# NPCX490M register map
File version: 1.0
Registers are 8-bit, read-write, reset 0x0 unless marked. A register's access mark holds for its fields unless they carry their own. Offsets are from the block's base; [hi:lo] are bit positions; {n}, {i} and the like mark numbered series.

## MDC
Base 0x4000C000
0x0A HEAD_BASEL 16-bit (reset mask 0xFF) — Header Base Low Register (HEAD_BASEL)
0x0C HEAD_BASEH 16-bit (reset mask 0xFF) — Header Base High Register (HEAD_BASEH)
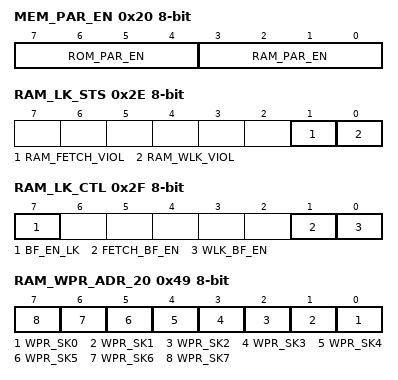
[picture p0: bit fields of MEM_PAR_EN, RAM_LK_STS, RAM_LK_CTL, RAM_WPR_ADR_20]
0x20 MEM_PAR_EN — Memory Parity Check Enable Register (MEM_PAR_EN)
  [7:4] ROM_PAR_EN — ROM Parity Check Enable
  [3:0] RAM_PAR_EN — RAM Parity Check Enable
0x22 FWSC — Firmware Scratch Register (FWSC)
0x2E RAM_LK_STS — RAM Lock Status Register (RAM_LK_STS)
  [1] RAM_FETCH_VIOL — RAM Fetch Violation
  [0] RAM_WLK_VIOL — RAM Write Lock Violation
0x2F RAM_LK_CTL — RAM Lock Control Register (RAM_LK_CTL)
  [7] BF_EN_LK — BusFault Trap Enable Lock
  [1] FETCH_BF_EN — RAM Fetch BusFault Trap Enable
  [0] WLK_BF_EN — RAM Write Lock BusFault Trap Enable
0x49 RAM_WPR_ADR_20 — RAM Write Protect Block Base Address nn Register (RAM_WPR_ADR_nn)
  [n] WPR_SK{n} (n=0..7) — Write Protect Sector {n}
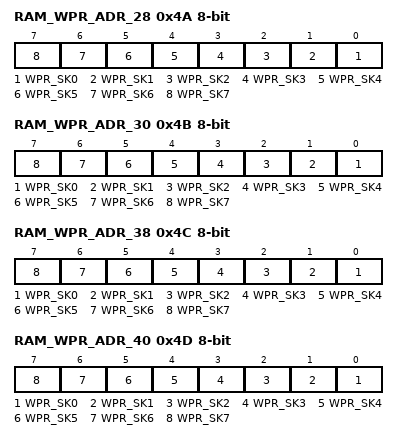
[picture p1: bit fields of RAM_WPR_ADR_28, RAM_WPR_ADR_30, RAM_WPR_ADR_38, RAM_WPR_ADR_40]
0x4A RAM_WPR_ADR_28 — RAM Write Protect Block Base Address nn Register (RAM_WPR_ADR_nn)
  [n] WPR_SK{n} (n=0..7) — Write Protect Sector {n}
0x4B RAM_WPR_ADR_30 — RAM Write Protect Block Base Address nn Register (RAM_WPR_ADR_nn)
  [n] WPR_SK{n} (n=0..7) — Write Protect Sector {n}
0x4C RAM_WPR_ADR_38 — RAM Write Protect Block Base Address nn Register (RAM_WPR_ADR_nn)
  [n] WPR_SK{n} (n=0..7) — Write Protect Sector {n}
0x4D RAM_WPR_ADR_40 — RAM Write Protect Block Base Address nn Register (RAM_WPR_ADR_nn)
  [n] WPR_SK{n} (n=0..7) — Write Protect Sector {n}
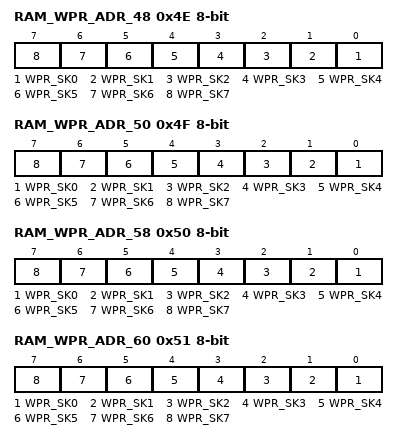
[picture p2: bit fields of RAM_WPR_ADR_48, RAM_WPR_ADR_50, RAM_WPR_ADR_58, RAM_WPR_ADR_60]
0x4E RAM_WPR_ADR_48 — RAM Write Protect Block Base Address nn Register (RAM_WPR_ADR_nn)
  [n] WPR_SK{n} (n=0..7) — Write Protect Sector {n}
0x4F RAM_WPR_ADR_50 — RAM Write Protect Block Base Address nn Register (RAM_WPR_ADR_nn)
  [n] WPR_SK{n} (n=0..7) — Write Protect Sector {n}
0x50 RAM_WPR_ADR_58 — RAM Write Protect Block Base Address nn Register (RAM_WPR_ADR_nn)
  [n] WPR_SK{n} (n=0..7) — Write Protect Sector {n}
0x51 RAM_WPR_ADR_60 — RAM Write Protect Block Base Address nn Register (RAM_WPR_ADR_nn)
  [n] WPR_SK{n} (n=0..7) — Write Protect Sector {n}
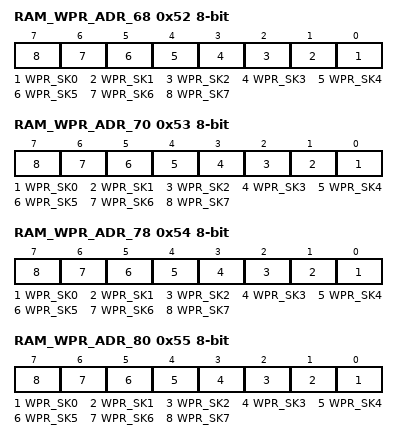
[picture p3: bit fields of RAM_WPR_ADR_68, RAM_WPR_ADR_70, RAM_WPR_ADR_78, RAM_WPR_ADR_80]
0x52 RAM_WPR_ADR_68 — RAM Write Protect Block Base Address nn Register (RAM_WPR_ADR_nn)
  [n] WPR_SK{n} (n=0..7) — Write Protect Sector {n}
0x53 RAM_WPR_ADR_70 — RAM Write Protect Block Base Address nn Register (RAM_WPR_ADR_nn)
  [n] WPR_SK{n} (n=0..7) — Write Protect Sector {n}
0x54 RAM_WPR_ADR_78 — RAM Write Protect Block Base Address nn Register (RAM_WPR_ADR_nn)
  [n] WPR_SK{n} (n=0..7) — Write Protect Sector {n}
0x55 RAM_WPR_ADR_80 — RAM Write Protect Block Base Address nn Register (RAM_WPR_ADR_nn)
  [n] WPR_SK{n} (n=0..7) — Write Protect Sector {n}
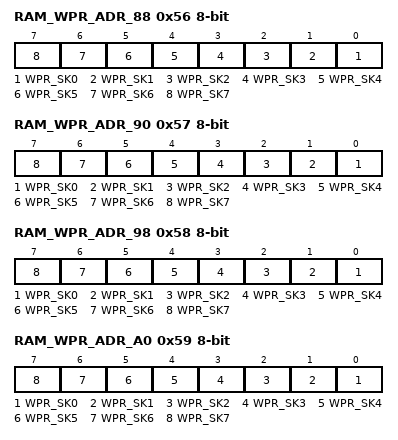
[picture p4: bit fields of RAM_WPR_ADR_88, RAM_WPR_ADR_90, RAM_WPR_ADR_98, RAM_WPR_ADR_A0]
0x56 RAM_WPR_ADR_88 — RAM Write Protect Block Base Address nn Register (RAM_WPR_ADR_nn)
  [n] WPR_SK{n} (n=0..7) — Write Protect Sector {n}
0x57 RAM_WPR_ADR_90 — RAM Write Protect Block Base Address nn Register (RAM_WPR_ADR_nn)
  [n] WPR_SK{n} (n=0..7) — Write Protect Sector {n}
0x58 RAM_WPR_ADR_98 — RAM Write Protect Block Base Address nn Register (RAM_WPR_ADR_nn)
  [n] WPR_SK{n} (n=0..7) — Write Protect Sector {n}
0x59 RAM_WPR_ADR_A0 — RAM Write Protect Block Base Address nn Register (RAM_WPR_ADR_nn)
  [n] WPR_SK{n} (n=0..7) — Write Protect Sector {n}
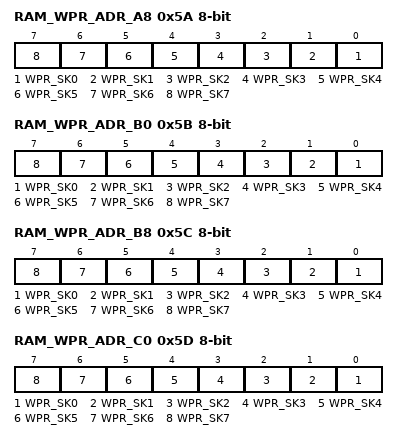
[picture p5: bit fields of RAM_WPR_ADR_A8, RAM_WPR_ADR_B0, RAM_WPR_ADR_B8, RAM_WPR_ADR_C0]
0x5A RAM_WPR_ADR_A8 — RAM Write Protect Block Base Address nn Register (RAM_WPR_ADR_nn)
  [n] WPR_SK{n} (n=0..7) — Write Protect Sector {n}
0x5B RAM_WPR_ADR_B0 — RAM Write Protect Block Base Address nn Register (RAM_WPR_ADR_nn)
  [n] WPR_SK{n} (n=0..7) — Write Protect Sector {n}
0x5C RAM_WPR_ADR_B8 — RAM Write Protect Block Base Address nn Register (RAM_WPR_ADR_nn)
  [n] WPR_SK{n} (n=0..7) — Write Protect Sector {n}
0x5D RAM_WPR_ADR_C0 — RAM Write Protect Block Base Address nn Register (RAM_WPR_ADR_nn)
  [n] WPR_SK{n} (n=0..7) — Write Protect Sector {n}
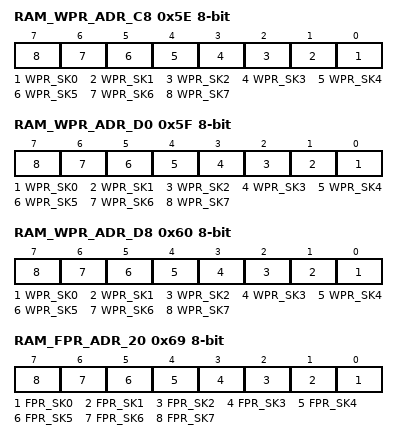
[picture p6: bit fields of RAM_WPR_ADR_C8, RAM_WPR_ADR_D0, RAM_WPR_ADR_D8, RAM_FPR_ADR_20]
0x5E RAM_WPR_ADR_C8 — RAM Write Protect Block Base Address nn Register (RAM_WPR_ADR_nn)
  [n] WPR_SK{n} (n=0..7) — Write Protect Sector {n}
0x5F RAM_WPR_ADR_D0 — RAM Write Protect Block Base Address nn Register (RAM_WPR_ADR_nn)
  [n] WPR_SK{n} (n=0..7) — Write Protect Sector {n}
0x60 RAM_WPR_ADR_D8 — RAM Write Protect Block Base Address nn Register (RAM_WPR_ADR_nn)
  [n] WPR_SK{n} (n=0..7) — Write Protect Sector {n}
0x69 RAM_FPR_ADR_20 — RAM Fetch Protect Block Base Address nn Register (RAM_FPR_ADR_nn)
  [n] FPR_SK{n} (n=0..7) — Fetch Protect Sector {n}
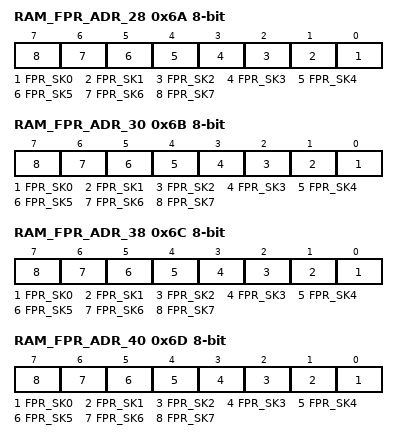
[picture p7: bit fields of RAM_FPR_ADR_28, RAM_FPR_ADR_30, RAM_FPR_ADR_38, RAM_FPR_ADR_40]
0x6A RAM_FPR_ADR_28 — RAM Fetch Protect Block Base Address nn Register (RAM_FPR_ADR_nn)
  [n] FPR_SK{n} (n=0..7) — Fetch Protect Sector {n}
0x6B RAM_FPR_ADR_30 — RAM Fetch Protect Block Base Address nn Register (RAM_FPR_ADR_nn)
  [n] FPR_SK{n} (n=0..7) — Fetch Protect Sector {n}
0x6C RAM_FPR_ADR_38 — RAM Fetch Protect Block Base Address nn Register (RAM_FPR_ADR_nn)
  [n] FPR_SK{n} (n=0..7) — Fetch Protect Sector {n}
0x6D RAM_FPR_ADR_40 — RAM Fetch Protect Block Base Address nn Register (RAM_FPR_ADR_nn)
  [n] FPR_SK{n} (n=0..7) — Fetch Protect Sector {n}
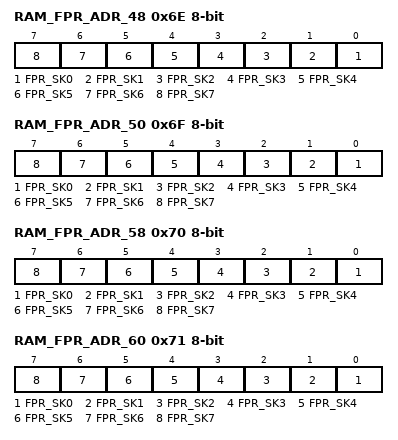
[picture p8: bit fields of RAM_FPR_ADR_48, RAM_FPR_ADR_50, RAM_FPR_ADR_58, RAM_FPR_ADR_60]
0x6E RAM_FPR_ADR_48 — RAM Fetch Protect Block Base Address nn Register (RAM_FPR_ADR_nn)
  [n] FPR_SK{n} (n=0..7) — Fetch Protect Sector {n}
0x6F RAM_FPR_ADR_50 — RAM Fetch Protect Block Base Address nn Register (RAM_FPR_ADR_nn)
  [n] FPR_SK{n} (n=0..7) — Fetch Protect Sector {n}
0x70 RAM_FPR_ADR_58 — RAM Fetch Protect Block Base Address nn Register (RAM_FPR_ADR_nn)
  [n] FPR_SK{n} (n=0..7) — Fetch Protect Sector {n}
0x71 RAM_FPR_ADR_60 — RAM Fetch Protect Block Base Address nn Register (RAM_FPR_ADR_nn)
  [n] FPR_SK{n} (n=0..7) — Fetch Protect Sector {n}
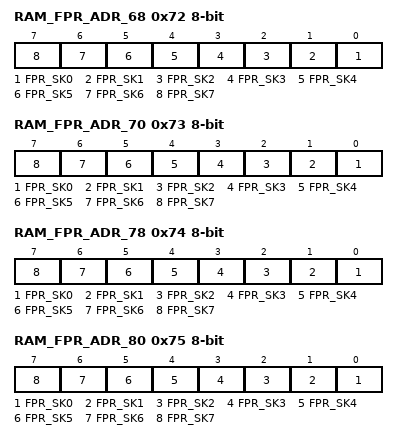
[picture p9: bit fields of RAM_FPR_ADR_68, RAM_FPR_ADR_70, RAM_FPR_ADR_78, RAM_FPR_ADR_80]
0x72 RAM_FPR_ADR_68 — RAM Fetch Protect Block Base Address nn Register (RAM_FPR_ADR_nn)
  [n] FPR_SK{n} (n=0..7) — Fetch Protect Sector {n}
0x73 RAM_FPR_ADR_70 — RAM Fetch Protect Block Base Address nn Register (RAM_FPR_ADR_nn)
  [n] FPR_SK{n} (n=0..7) — Fetch Protect Sector {n}
0x74 RAM_FPR_ADR_78 — RAM Fetch Protect Block Base Address nn Register (RAM_FPR_ADR_nn)
  [n] FPR_SK{n} (n=0..7) — Fetch Protect Sector {n}
0x75 RAM_FPR_ADR_80 — RAM Fetch Protect Block Base Address nn Register (RAM_FPR_ADR_nn)
  [n] FPR_SK{n} (n=0..7) — Fetch Protect Sector {n}
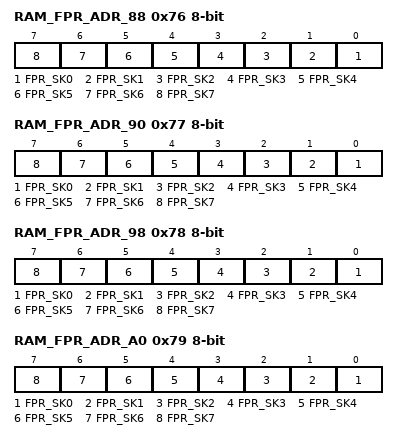
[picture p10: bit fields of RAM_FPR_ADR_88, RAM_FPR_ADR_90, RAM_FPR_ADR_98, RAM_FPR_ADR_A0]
0x76 RAM_FPR_ADR_88 — RAM Fetch Protect Block Base Address nn Register (RAM_FPR_ADR_nn)
  [n] FPR_SK{n} (n=0..7) — Fetch Protect Sector {n}
0x77 RAM_FPR_ADR_90 — RAM Fetch Protect Block Base Address nn Register (RAM_FPR_ADR_nn)
  [n] FPR_SK{n} (n=0..7) — Fetch Protect Sector {n}
0x78 RAM_FPR_ADR_98 — RAM Fetch Protect Block Base Address nn Register (RAM_FPR_ADR_nn)
  [n] FPR_SK{n} (n=0..7) — Fetch Protect Sector {n}
0x79 RAM_FPR_ADR_A0 — RAM Fetch Protect Block Base Address nn Register (RAM_FPR_ADR_nn)
  [n] FPR_SK{n} (n=0..7) — Fetch Protect Sector {n}
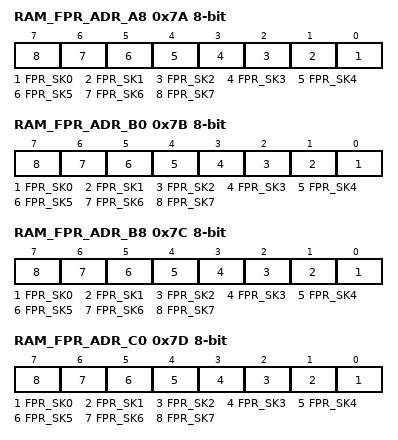
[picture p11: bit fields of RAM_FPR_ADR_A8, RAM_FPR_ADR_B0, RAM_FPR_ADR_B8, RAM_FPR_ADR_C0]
0x7A RAM_FPR_ADR_A8 — RAM Fetch Protect Block Base Address nn Register (RAM_FPR_ADR_nn)
  [n] FPR_SK{n} (n=0..7) — Fetch Protect Sector {n}
0x7B RAM_FPR_ADR_B0 — RAM Fetch Protect Block Base Address nn Register (RAM_FPR_ADR_nn)
  [n] FPR_SK{n} (n=0..7) — Fetch Protect Sector {n}
0x7C RAM_FPR_ADR_B8 — RAM Fetch Protect Block Base Address nn Register (RAM_FPR_ADR_nn)
  [n] FPR_SK{n} (n=0..7) — Fetch Protect Sector {n}
0x7D RAM_FPR_ADR_C0 — RAM Fetch Protect Block Base Address nn Register (RAM_FPR_ADR_nn)
  [n] FPR_SK{n} (n=0..7) — Fetch Protect Sector {n}
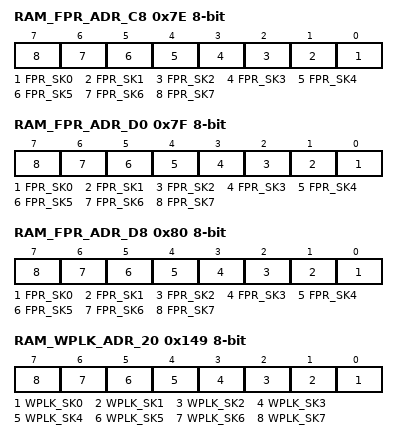
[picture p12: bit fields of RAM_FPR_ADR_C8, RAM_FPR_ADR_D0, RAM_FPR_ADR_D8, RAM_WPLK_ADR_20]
0x7E RAM_FPR_ADR_C8 — RAM Fetch Protect Block Base Address nn Register (RAM_FPR_ADR_nn)
  [n] FPR_SK{n} (n=0..7) — Fetch Protect Sector {n}
0x7F RAM_FPR_ADR_D0 — RAM Fetch Protect Block Base Address nn Register (RAM_FPR_ADR_nn)
  [n] FPR_SK{n} (n=0..7) — Fetch Protect Sector {n}
0x80 RAM_FPR_ADR_D8 — RAM Fetch Protect Block Base Address nn Register (RAM_FPR_ADR_nn)
  [n] FPR_SK{n} (n=0..7) — Fetch Protect Sector {n}
0x149 RAM_WPLK_ADR_20 — RAM Write Protect Lock Block Base Address nn Register (RAM_WPLK_ADR_nn)
  [n] WPLK_SK{n} (n=0..7) — Write Protect Lock Sector {n}
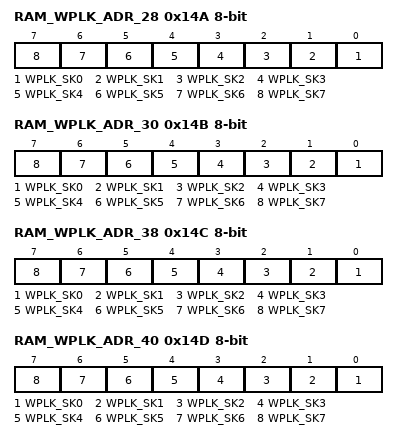
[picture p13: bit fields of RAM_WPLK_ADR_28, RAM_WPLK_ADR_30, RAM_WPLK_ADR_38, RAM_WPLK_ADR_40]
0x14A RAM_WPLK_ADR_28 — RAM Write Protect Lock Block Base Address nn Register (RAM_WPLK_ADR_nn)
  [n] WPLK_SK{n} (n=0..7) — Write Protect Lock Sector {n}
0x14B RAM_WPLK_ADR_30 — RAM Write Protect Lock Block Base Address nn Register (RAM_WPLK_ADR_nn)
  [n] WPLK_SK{n} (n=0..7) — Write Protect Lock Sector {n}
0x14C RAM_WPLK_ADR_38 — RAM Write Protect Lock Block Base Address nn Register (RAM_WPLK_ADR_nn)
  [n] WPLK_SK{n} (n=0..7) — Write Protect Lock Sector {n}
0x14D RAM_WPLK_ADR_40 — RAM Write Protect Lock Block Base Address nn Register (RAM_WPLK_ADR_nn)
  [n] WPLK_SK{n} (n=0..7) — Write Protect Lock Sector {n}
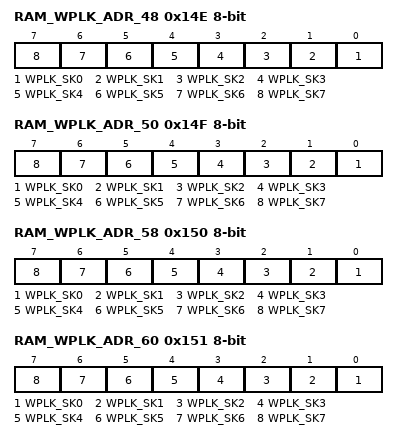
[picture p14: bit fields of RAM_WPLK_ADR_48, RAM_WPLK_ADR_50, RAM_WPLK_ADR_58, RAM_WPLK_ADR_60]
0x14E RAM_WPLK_ADR_48 — RAM Write Protect Lock Block Base Address nn Register (RAM_WPLK_ADR_nn)
  [n] WPLK_SK{n} (n=0..7) — Write Protect Lock Sector {n}
0x14F RAM_WPLK_ADR_50 — RAM Write Protect Lock Block Base Address nn Register (RAM_WPLK_ADR_nn)
  [n] WPLK_SK{n} (n=0..7) — Write Protect Lock Sector {n}
0x150 RAM_WPLK_ADR_58 — RAM Write Protect Lock Block Base Address nn Register (RAM_WPLK_ADR_nn)
  [n] WPLK_SK{n} (n=0..7) — Write Protect Lock Sector {n}
0x151 RAM_WPLK_ADR_60 — RAM Write Protect Lock Block Base Address nn Register (RAM_WPLK_ADR_nn)
  [n] WPLK_SK{n} (n=0..7) — Write Protect Lock Sector {n}
0x152 RAM_WPLK_ADR_68 — RAM Write Protect Lock Block Base Address nn Register (RAM_WPLK_ADR_nn)
  [n] WPLK_SK{n} (n=0..7) — Write Protect Lock Sector {n}
0x153 RAM_WPLK_ADR_70 — RAM Write Protect Lock Block Base Address nn Register (RAM_WPLK_ADR_nn)
  [n] WPLK_SK{n} (n=0..7) — Write Protect Lock Sector {n}
0x154 RAM_WPLK_ADR_78 — RAM Write Protect Lock Block Base Address nn Register (RAM_WPLK_ADR_nn)
  [n] WPLK_SK{n} (n=0..7) — Write Protect Lock Sector {n}
0x155 RAM_WPLK_ADR_80 — RAM Write Protect Lock Block Base Address nn Register (RAM_WPLK_ADR_nn)
  [n] WPLK_SK{n} (n=0..7) — Write Protect Lock Sector {n}
0x156 RAM_WPLK_ADR_88 — RAM Write Protect Lock Block Base Address nn Register (RAM_WPLK_ADR_nn)
  [n] WPLK_SK{n} (n=0..7) — Write Protect Lock Sector {n}
0x157 RAM_WPLK_ADR_90 — RAM Write Protect Lock Block Base Address nn Register (RAM_WPLK_ADR_nn)
  [n] WPLK_SK{n} (n=0..7) — Write Protect Lock Sector {n}
0x158 RAM_WPLK_ADR_98 — RAM Write Protect Lock Block Base Address nn Register (RAM_WPLK_ADR_nn)
  [n] WPLK_SK{n} (n=0..7) — Write Protect Lock Sector {n}
0x159 RAM_WPLK_ADR_A0 — RAM Write Protect Lock Block Base Address nn Register (RAM_WPLK_ADR_nn)
  [n] WPLK_SK{n} (n=0..7) — Write Protect Lock Sector {n}
0x15A RAM_WPLK_ADR_A8 — RAM Write Protect Lock Block Base Address nn Register (RAM_WPLK_ADR_nn)
  [n] WPLK_SK{n} (n=0..7) — Write Protect Lock Sector {n}
0x15B RAM_WPLK_ADR_B0 — RAM Write Protect Lock Block Base Address nn Register (RAM_WPLK_ADR_nn)
  [n] WPLK_SK{n} (n=0..7) — Write Protect Lock Sector {n}
0x15C RAM_WPLK_ADR_B8 — RAM Write Protect Lock Block Base Address nn Register (RAM_WPLK_ADR_nn)
  [n] WPLK_SK{n} (n=0..7) — Write Protect Lock Sector {n}
0x15D RAM_WPLK_ADR_C0 — RAM Write Protect Lock Block Base Address nn Register (RAM_WPLK_ADR_nn)
  [n] WPLK_SK{n} (n=0..7) — Write Protect Lock Sector {n}
0x15E RAM_WPLK_ADR_C8 — RAM Write Protect Lock Block Base Address nn Register (RAM_WPLK_ADR_nn)
  [n] WPLK_SK{n} (n=0..7) — Write Protect Lock Sector {n}
0x15F RAM_WPLK_ADR_D0 — RAM Write Protect Lock Block Base Address nn Register (RAM_WPLK_ADR_nn)
  [n] WPLK_SK{n} (n=0..7) — Write Protect Lock Sector {n}
0x160 RAM_WPLK_ADR_D8 — RAM Write Protect Lock Block Base Address nn Register (RAM_WPLK_ADR_nn)
  [n] WPLK_SK{n} (n=0..7) — Write Protect Lock Sector {n}
0x169 RAM_FPLK_ADR_20 — RAM Fetch Protect Lock Block Base Address nn Register (RAM_FPLK_ADR_nn)
  [n] FPLK_SK{n} (n=0..7) — Fetch Protect Lock Sector {n}
0x16A RAM_FPLK_ADR_28 — RAM Fetch Protect Lock Block Base Address nn Register (RAM_FPLK_ADR_nn)
  [n] FPLK_SK{n} (n=0..7) — Fetch Protect Lock Sector {n}
0x16B RAM_FPLK_ADR_30 — RAM Fetch Protect Lock Block Base Address nn Register (RAM_FPLK_ADR_nn)
  [n] FPLK_SK{n} (n=0..7) — Fetch Protect Lock Sector {n}
0x16C RAM_FPLK_ADR_38 — RAM Fetch Protect Lock Block Base Address nn Register (RAM_FPLK_ADR_nn)
  [n] FPLK_SK{n} (n=0..7) — Fetch Protect Lock Sector {n}
0x16D RAM_FPLK_ADR_40 — RAM Fetch Protect Lock Block Base Address nn Register (RAM_FPLK_ADR_nn)
  [n] FPLK_SK{n} (n=0..7) — Fetch Protect Lock Sector {n}
0x16E RAM_FPLK_ADR_48 — RAM Fetch Protect Lock Block Base Address nn Register (RAM_FPLK_ADR_nn)
  [n] FPLK_SK{n} (n=0..7) — Fetch Protect Lock Sector {n}
0x16F RAM_FPLK_ADR_50 — RAM Fetch Protect Lock Block Base Address nn Register (RAM_FPLK_ADR_nn)
  [n] FPLK_SK{n} (n=0..7) — Fetch Protect Lock Sector {n}
0x170 RAM_FPLK_ADR_58 — RAM Fetch Protect Lock Block Base Address nn Register (RAM_FPLK_ADR_nn)
  [n] FPLK_SK{n} (n=0..7) — Fetch Protect Lock Sector {n}
0x171 RAM_FPLK_ADR_60 — RAM Fetch Protect Lock Block Base Address nn Register (RAM_FPLK_ADR_nn)
  [n] FPLK_SK{n} (n=0..7) — Fetch Protect Lock Sector {n}
0x172 RAM_FPLK_ADR_68 — RAM Fetch Protect Lock Block Base Address nn Register (RAM_FPLK_ADR_nn)
  [n] FPLK_SK{n} (n=0..7) — Fetch Protect Lock Sector {n}
0x173 RAM_FPLK_ADR_70 — RAM Fetch Protect Lock Block Base Address nn Register (RAM_FPLK_ADR_nn)
  [n] FPLK_SK{n} (n=0..7) — Fetch Protect Lock Sector {n}
0x174 RAM_FPLK_ADR_78 — RAM Fetch Protect Lock Block Base Address nn Register (RAM_FPLK_ADR_nn)
  [n] FPLK_SK{n} (n=0..7) — Fetch Protect Lock Sector {n}
0x175 RAM_FPLK_ADR_80 — RAM Fetch Protect Lock Block Base Address nn Register (RAM_FPLK_ADR_nn)
  [n] FPLK_SK{n} (n=0..7) — Fetch Protect Lock Sector {n}
0x176 RAM_FPLK_ADR_88 — RAM Fetch Protect Lock Block Base Address nn Register (RAM_FPLK_ADR_nn)
  [n] FPLK_SK{n} (n=0..7) — Fetch Protect Lock Sector {n}
0x177 RAM_FPLK_ADR_90 — RAM Fetch Protect Lock Block Base Address nn Register (RAM_FPLK_ADR_nn)
  [n] FPLK_SK{n} (n=0..7) — Fetch Protect Lock Sector {n}
0x178 RAM_FPLK_ADR_98 — RAM Fetch Protect Lock Block Base Address nn Register (RAM_FPLK_ADR_nn)
  [n] FPLK_SK{n} (n=0..7) — Fetch Protect Lock Sector {n}
0x179 RAM_FPLK_ADR_A0 — RAM Fetch Protect Lock Block Base Address nn Register (RAM_FPLK_ADR_nn)
  [n] FPLK_SK{n} (n=0..7) — Fetch Protect Lock Sector {n}
0x17A RAM_FPLK_ADR_A8 — RAM Fetch Protect Lock Block Base Address nn Register (RAM_FPLK_ADR_nn)
  [n] FPLK_SK{n} (n=0..7) — Fetch Protect Lock Sector {n}
0x17B RAM_FPLK_ADR_B0 — RAM Fetch Protect Lock Block Base Address nn Register (RAM_FPLK_ADR_nn)
  [n] FPLK_SK{n} (n=0..7) — Fetch Protect Lock Sector {n}
0x17C RAM_FPLK_ADR_B8 — RAM Fetch Protect Lock Block Base Address nn Register (RAM_FPLK_ADR_nn)
  [n] FPLK_SK{n} (n=0..7) — Fetch Protect Lock Sector {n}
0x17D RAM_FPLK_ADR_C0 — RAM Fetch Protect Lock Block Base Address nn Register (RAM_FPLK_ADR_nn)
  [n] FPLK_SK{n} (n=0..7) — Fetch Protect Lock Sector {n}
0x17E RAM_FPLK_ADR_C8 — RAM Fetch Protect Lock Block Base Address nn Register (RAM_FPLK_ADR_nn)
  [n] FPLK_SK{n} (n=0..7) — Fetch Protect Lock Sector {n}
0x17F RAM_FPLK_ADR_D0 — RAM Fetch Protect Lock Block Base Address nn Register (RAM_FPLK_ADR_nn)
  [n] FPLK_SK{n} (n=0..7) — Fetch Protect Lock Sector {n}
0x180 RAM_FPLK_ADR_D8 — RAM Fetch Protect Lock Block Base Address nn Register (RAM_FPLK_ADR_nn)
  [n] FPLK_SK{n} (n=0..7) — Fetch Protect Lock Sector {n}
